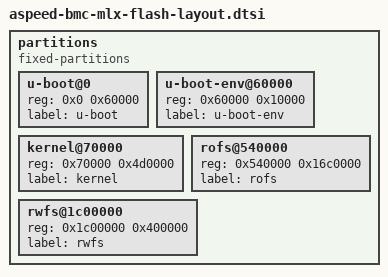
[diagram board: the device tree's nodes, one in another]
// SPDX-License-Identifier: GPL-2.0+

partitions {
	compatible = "fixed-partitions";
	#address-cells = <1>;
	#size-cells = <1>;

	u-boot@0 {
		reg = <0x0 0x60000>;
		label = "u-boot";
	};

	u-boot-env@60000 {
		reg = <0x60000 0x10000>;
		label = "u-boot-env";
	};

	kernel@70000 {
		reg = <0x70000 0x4d0000>;
		label = "kernel";
	};

	rofs@540000 {
		reg = <0x540000 0x16c0000>;
		label = "rofs";
	};

	rwfs@1c00000 {
		reg = <0x1c00000 0x400000>;
		label = "rwfs";
	};
};
